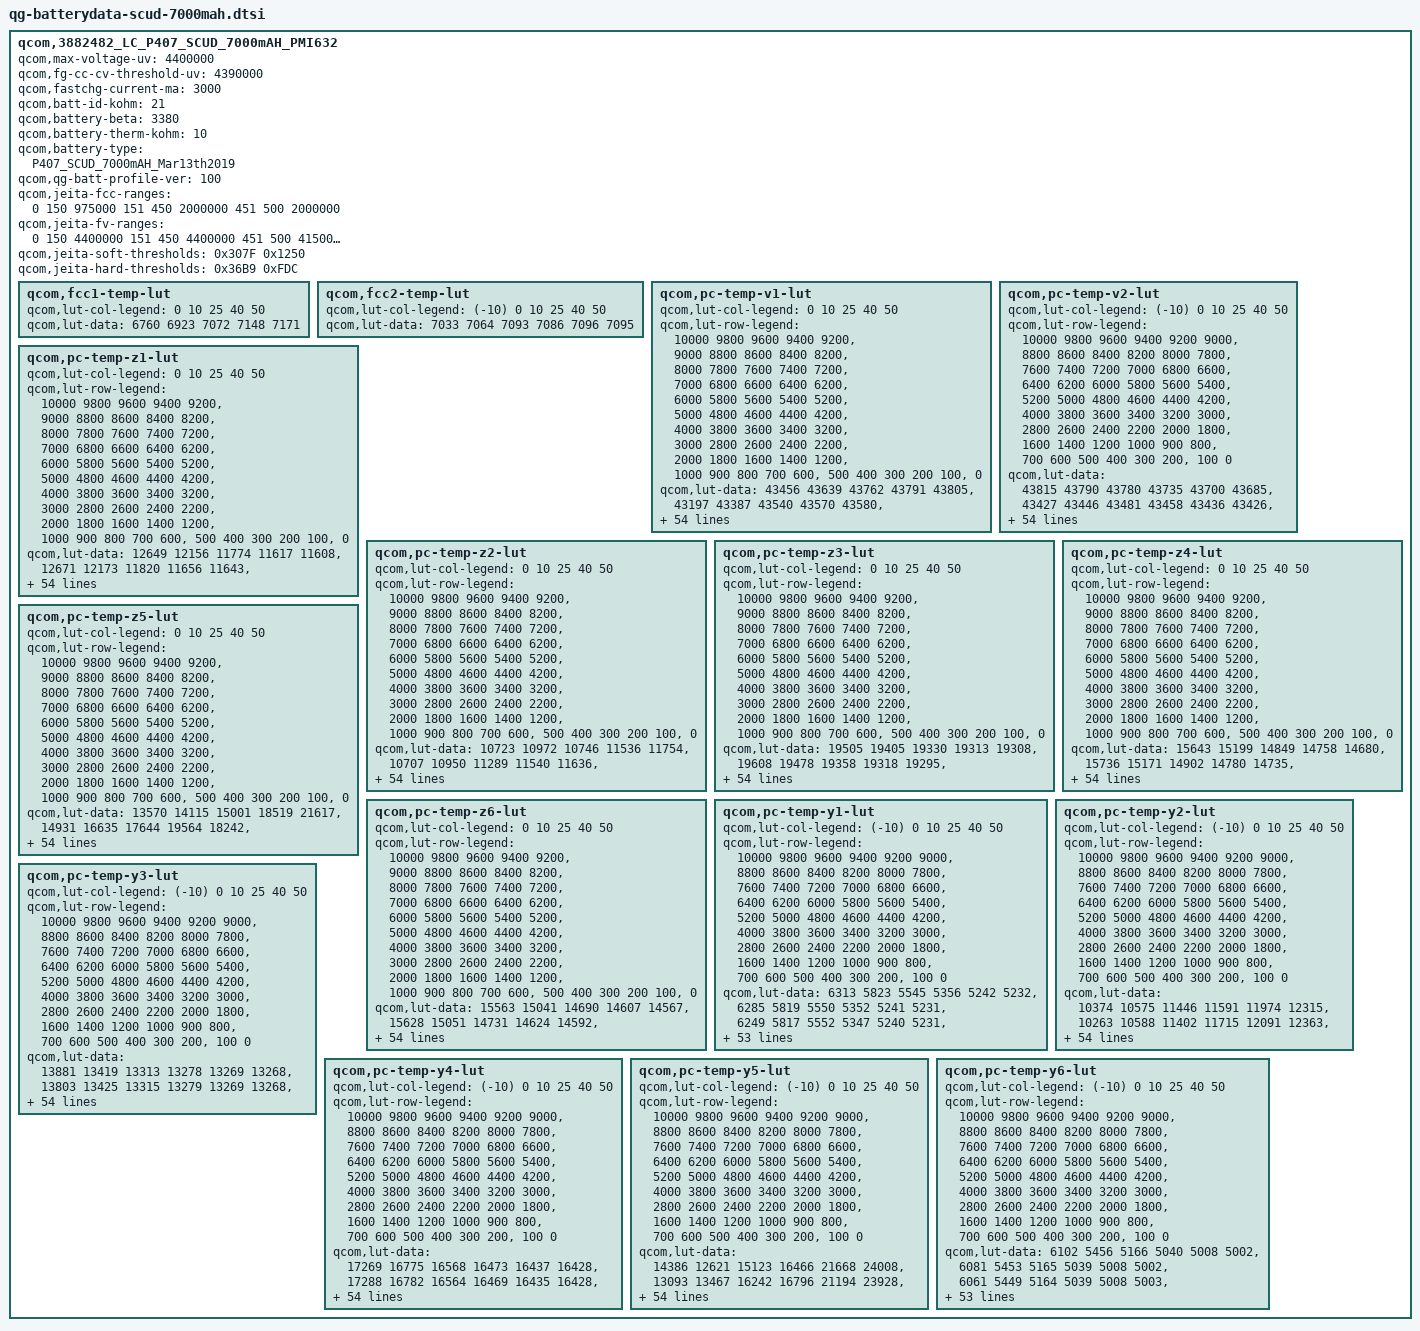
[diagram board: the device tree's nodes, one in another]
qcom,3882482_LC_P407_SCUD_7000mAH_PMI632 {
    /* 3882482_LC_P407_SCUD_7000mAH_PMI632_averaged_MasterSlave_Mar13th2019 */
    qcom,max-voltage-uv = <4400000>;
    qcom,fg-cc-cv-threshold-uv = <4390000>;
    qcom,fastchg-current-ma = <3000>;
    qcom,batt-id-kohm = <21>;
    qcom,battery-beta = <3380>;
    qcom,battery-therm-kohm = <10>;
    qcom,battery-type = "P407_SCUD_7000mAH_Mar13th2019";
    qcom,qg-batt-profile-ver = <100>;

	qcom,jeita-fcc-ranges = <0   150   975000
				151  450  2000000
				451  500  2000000>;
	qcom,jeita-fv-ranges =  <0   150  4400000
				151  450  4400000
				451  500  4150000>;

	/* COOL = 15 DegC, WARM = 45 DegC */
	qcom,jeita-soft-thresholds = <0x307F 0x1250>;
	/* COLD = 0 DegC, HOT = 50 DegC */
	qcom,jeita-hard-thresholds = <0x36B9 0xFDC>;
	qcom,fcc1-temp-lut {
		qcom,lut-col-legend = <0 10 25 40 50>;
		qcom,lut-data = <6760 6923 7072 7148 7171>;
	};

	qcom,fcc2-temp-lut {
		qcom,lut-col-legend = <(-10) 0 10 25 40 50>;
		qcom,lut-data = <7033 7064 7093 7086 7096 7095>;
	};

	qcom,pc-temp-v1-lut {
		qcom,lut-col-legend = <0 10 25 40 50>;
		qcom,lut-row-legend = <10000 9800 9600 9400 9200>,
			<9000 8800 8600 8400 8200>,
			<8000 7800 7600 7400 7200>,
			<7000 6800 6600 6400 6200>,
			<6000 5800 5600 5400 5200>,
			<5000 4800 4600 4400 4200>,
			<4000 3800 3600 3400 3200>,
			<3000 2800 2600 2400 2200>,
			<2000 1800 1600 1400 1200>,
			<1000 900 800 700 600>,
			<500 400 300 200 100>,
			<0>;
		qcom,lut-data = <43456 43639 43762 43791 43805>,
			<43197 43387 43540 43570 43580>,
			<42951 43141 43302 43344 43359>,
			<42713 42901 43063 43115 43132>,
			<42482 42666 42826 42884 42903>,
			<42255 42433 42590 42648 42670>,
			<42033 42203 42356 42413 42436>,
			<41814 41977 42122 42180 42204>,
			<41599 41756 41893 41950 41974>,
			<41398 41539 41666 41723 41746>,
			<41218 41333 41443 41497 41520>,
			<41031 41143 41232 41277 41299>,
			<40807 40947 41033 41062 41082>,
			<40553 40726 40832 40855 40873>,
			<40320 40492 40617 40649 40667>,
			<40115 40282 40405 40446 40466>,
			<39933 40095 40213 40254 40275>,
			<39780 39927 40035 40076 40095>,
			<39650 39780 39869 39905 39923>,
			<39525 39647 39726 39747 39759>,
			<39399 39507 39579 39594 39600>,
			<39277 39360 39376 39401 39415>,
			<39157 39201 39117 39128 39169>,
			<39039 39008 38904 38890 38939>,
			<38925 38794 38745 38760 38794>,
			<38813 38638 38619 38663 38683>,
			<38704 38532 38532 38569 38578>,
			<38604 38452 38466 38476 38476>,
			<38512 38395 38402 38390 38382>,
			<38431 38353 38336 38307 38295>,
			<38369 38312 38274 38232 38215>,
			<38318 38271 38220 38165 38144>,
			<38273 38232 38170 38107 38082>,
			<38234 38194 38123 38052 38023>,
			<38199 38159 38081 38005 37968>,
			<38164 38124 38040 37960 37914>,
			<38132 38093 38000 37912 37855>,
			<38093 38057 37959 37862 37794>,
			<38039 37998 37901 37799 37723>,
			<37966 37903 37810 37713 37639>,
			<37877 37796 37703 37611 37542>,
			<37758 37681 37591 37498 37430>,
			<37621 37549 37464 37367 37301>,
			<37460 37386 37309 37213 37146>,
			<37317 37245 37165 37073 37008>,
			<37233 37161 37079 36984 36925>,
			<37203 37132 37052 36965 36902>,
			<37184 37110 37032 36949 36886>,
			<37158 37094 37019 36931 36869>,
			<37115 37052 36983 36880 36810>,
			<36909 36832 36789 36633 36540>,
			<36466 36402 36378 36206 36107>,
			<35897 35835 35830 35641 35538>,
			<35125 35065 35087 34873 34765>,
			<33916 33864 33953 33695 33574>,
			<30000 30000 30000 30000 30000>;
	};

	qcom,pc-temp-v2-lut {
		qcom,lut-col-legend = <(-10) 0 10 25 40 50>;
		qcom,lut-row-legend = <10000 9800 9600 9400 9200 9000>,
			<8800 8600 8400 8200 8000 7800>,
			<7600 7400 7200 7000 6800 6600>,
			<6400 6200 6000 5800 5600 5400>,
			<5200 5000 4800 4600 4400 4200>,
			<4000 3800 3600 3400 3200 3000>,
			<2800 2600 2400 2200 2000 1800>,
			<1600 1400 1200 1000 900 800>,
			<700 600 500 400 300 200>,
			<100 0>;
		qcom,lut-data = <43815 43790 43780 43735 43700 43685>,
			<43427 43446 43481 43458 43436 43426>,
			<43077 43129 43199 43194 43181 43174>,
			<42764 42843 42936 42943 42935 42932>,
			<42483 42586 42692 42707 42700 42698>,
			<42235 42338 42452 42473 42466 42465>,
			<42027 42091 42213 42239 42232 42232>,
			<41833 41851 41977 42007 42000 42000>,
			<41599 41613 41748 41778 41771 41772>,
			<41319 41375 41523 41551 41545 41546>,
			<41099 41162 41305 41329 41322 41323>,
			<40985 40997 41101 41113 41105 41105>,
			<40883 40836 40900 40901 40891 40891>,
			<40638 40616 40692 40696 40686 40686>,
			<40130 40332 40477 40495 40485 40487>,
			<39720 40059 40263 40295 40291 40294>,
			<39516 39816 40052 40092 40099 40107>,
			<39356 39591 39842 39900 39916 39927>,
			<39190 39397 39630 39734 39748 39759>,
			<39027 39223 39417 39585 39592 39599>,
			<38863 39053 39217 39406 39409 39415>,
			<38686 38880 39026 39161 39173 39183>,
			<38521 38716 38853 38922 38945 38959>,
			<38401 38568 38703 38754 38774 38786>,
			<38307 38429 38569 38619 38631 38640>,
			<38227 38307 38450 38500 38509 38515>,
			<38159 38196 38343 38395 38402 38407>,
			<38099 38104 38245 38298 38307 38310>,
			<38042 38038 38156 38208 38218 38220>,
			<37989 37985 38073 38124 38138 38137>,
			<37938 37937 37995 38049 38064 38063>,
			<37888 37893 37921 37981 37996 37993>,
			<37839 37852 37860 37918 37932 37927>,
			<37788 37811 37816 37857 37871 37865>,
			<37739 37771 37781 37801 37810 37804>,
			<37686 37726 37743 37744 37736 37720>,
			<37627 37675 37703 37686 37643 37606>,
			<37564 37618 37659 37625 37550 37495>,
			<37494 37555 37604 37557 37469 37408>,
			<37420 37483 37538 37485 37392 37329>,
			<37343 37401 37457 37405 37311 37246>,
			<37263 37304 37352 37312 37222 37159>,
			<37183 37189 37231 37202 37114 37050>,
			<37105 37065 37096 37068 36980 36916>,
			<37025 36950 36964 36932 36857 36799>,
			<36932 36846 36876 36883 36823 36768>,
			<36880 36799 36839 36866 36812 36753>,
			<36829 36744 36808 36848 36792 36735>,
			<36764 36685 36761 36816 36754 36697>,
			<36670 36590 36668 36750 36673 36607>,
			<36503 36405 36458 36532 36392 36311>,
			<36206 36056 36038 36090 35919 35838>,
			<35717 35505 35429 35497 35292 35209>,
			<34992 34699 34606 34699 34427 34348>,
			<33903 33435 33349 33490 33089 33051>,
			<31795 29561 29447 30820 29743 29527>;
	};

	qcom,pc-temp-z1-lut {
		qcom,lut-col-legend = <0 10 25 40 50>;
		qcom,lut-row-legend = <10000 9800 9600 9400 9200>,
			<9000 8800 8600 8400 8200>,
			<8000 7800 7600 7400 7200>,
			<7000 6800 6600 6400 6200>,
			<6000 5800 5600 5400 5200>,
			<5000 4800 4600 4400 4200>,
			<4000 3800 3600 3400 3200>,
			<3000 2800 2600 2400 2200>,
			<2000 1800 1600 1400 1200>,
			<1000 900 800 700 600>,
			<500 400 300 200 100>,
			<0>;
		qcom,lut-data = <12649 12156 11774 11617 11608>,
			<12671 12173 11820 11656 11643>,
			<12690 12182 11818 11662 11654>,
			<12705 12189 11810 11669 11661>,
			<12709 12197 11808 11673 11665>,
			<12710 12199 11806 11673 11668>,
			<12710 12191 11805 11674 11671>,
			<12700 12182 11803 11676 11674>,
			<12682 12179 11801 11680 11678>,
			<12677 12177 11802 11683 11682>,
			<12687 12179 11803 11687 11687>,
			<12695 12188 11805 11689 11690>,
			<12696 12194 11808 11691 11692>,
			<12693 12188 11810 11692 11692>,
			<12689 12175 11809 11692 11693>,
			<12670 12167 11807 11692 11694>,
			<12648 12164 11806 11692 11694>,
			<12646 12165 11806 11692 11694>,
			<12655 12171 11806 11692 11694>,
			<12663 12179 11809 11693 11694>,
			<12669 12182 11812 11694 11696>,
			<12673 12183 11814 11694 11697>,
			<12669 12184 11815 11695 11697>,
			<12658 12188 11816 11697 11698>,
			<12651 12193 11818 11699 11699>,
			<12659 12195 11821 11701 11701>,
			<12673 12192 11824 11704 11702>,
			<12678 12189 11827 11707 11702>,
			<12676 12192 11830 11709 11703>,
			<12673 12202 11834 11711 11705>,
			<12670 12209 11838 11712 11708>,
			<12664 12207 11841 11714 11710>,
			<12662 12204 11844 11716 11712>,
			<12674 12206 11847 11718 11713>,
			<12692 12209 11850 11720 11715>,
			<12699 12214 11853 11721 11716>,
			<12700 12223 11856 11723 11717>,
			<12702 12234 11859 11725 11718>,
			<12704 12239 11862 11727 11719>,
			<12708 12246 11865 11729 11720>,
			<12711 12248 11868 11730 11721>,
			<12716 12244 11874 11731 11722>,
			<12719 12242 11879 11731 11722>,
			<12715 12243 11881 11734 11724>,
			<12693 12251 11885 11738 11726>,
			<12676 12242 11887 11740 11727>,
			<12684 12241 11889 11740 11727>,
			<12694 12241 11889 11740 11728>,
			<12688 12246 11886 11742 11728>,
			<12691 12249 11897 11743 11729>,
			<12685 12252 11897 11746 11730>,
			<12690 12273 11902 11750 11736>,
			<12746 12281 11920 11758 11741>,
			<12713 12315 11934 11768 11751>,
			<12713 12315 11934 11768 11751>,
			<12713 12315 11934 11768 11751>;
	};

	qcom,pc-temp-z2-lut {
		qcom,lut-col-legend = <0 10 25 40 50>;
		qcom,lut-row-legend = <10000 9800 9600 9400 9200>,
			<9000 8800 8600 8400 8200>,
			<8000 7800 7600 7400 7200>,
			<7000 6800 6600 6400 6200>,
			<6000 5800 5600 5400 5200>,
			<5000 4800 4600 4400 4200>,
			<4000 3800 3600 3400 3200>,
			<3000 2800 2600 2400 2200>,
			<2000 1800 1600 1400 1200>,
			<1000 900 800 700 600>,
			<500 400 300 200 100>,
			<0>;
		qcom,lut-data = <10723 10972 10746 11536 11754>,
			<10707 10950 11289 11540 11636>,
			<10729 10934 11301 11622 11674>,
			<10763 10922 11303 11725 11673>,
			<10802 10910 11309 11761 11711>,
			<10849 10895 11321 11756 11891>,
			<10884 10869 11319 11752 12013>,
			<10912 10849 11298 11720 11983>,
			<10937 10847 11278 11661 11920>,
			<10944 10847 11264 11633 11860>,
			<10937 10847 11255 11621 11731>,
			<10924 10844 11256 11617 11606>,
			<10884 10840 11264 11648 11555>,
			<10813 10836 11275 11697 11547>,
			<10781 10833 11297 11650 11572>,
			<10779 10841 11329 11492 11601>,
			<10779 10913 11356 11429 11625>,
			<10778 10994 11386 11470 11648>,
			<10778 11036 11406 11514 11666>,
			<10777 11066 11414 11527 11691>,
			<10763 11075 11422 11536 11752>,
			<10743 11071 11430 11572 11793>,
			<10731 11066 11439 11725 11811>,
			<10720 11070 11438 11824 11796>,
			<10713 11080 11421 11709 11801>,
			<10718 11089 11405 11518 11848>,
			<10733 11101 11406 11516 11880>,
			<10746 11109 11413 11721 11910>,
			<10755 11108 11421 11855 11909>,
			<10764 11104 11448 11828 11769>,
			<10777 11102 11473 11777 11586>,
			<10794 11107 11462 11737 11555>,
			<10811 11116 11426 11697 11531>,
			<10825 11124 11414 11679 11516>,
			<10839 11132 11435 11701 11568>,
			<10857 11141 11460 11739 11655>,
			<10882 11151 11468 11774 11709>,
			<10907 11162 11474 11812 11754>,
			<10927 11175 11489 11850 11801>,
			<10947 11193 11538 11900 11897>,
			<10967 11204 11575 11934 11980>,
			<10991 11205 11572 11894 11963>,
			<11027 11207 11565 11817 11909>,
			<11089 11225 11571 11814 11878>,
			<11463 11390 11632 11840 11914>,
			<11787 11570 11666 11916 11943>,
			<11743 11578 11677 11890 11877>,
			<11470 11571 11658 11842 11903>,
			<11412 11889 11824 11848 11968>,
			<11191 11823 11783 12026 12287>,
			<11031 11718 11930 12215 11813>,
			<11401 11719 11973 11961 11600>,
			<11000 11694 11904 11823 11405>,
			<10723 11540 11946 11588 11426>,
			<10723 11540 11946 11588 11426>,
			<10723 11540 11946 11588 11426>;
	};

	qcom,pc-temp-z3-lut {
		qcom,lut-col-legend = <0 10 25 40 50>;
		qcom,lut-row-legend = <10000 9800 9600 9400 9200>,
			<9000 8800 8600 8400 8200>,
			<8000 7800 7600 7400 7200>,
			<7000 6800 6600 6400 6200>,
			<6000 5800 5600 5400 5200>,
			<5000 4800 4600 4400 4200>,
			<4000 3800 3600 3400 3200>,
			<3000 2800 2600 2400 2200>,
			<2000 1800 1600 1400 1200>,
			<1000 900 800 700 600>,
			<500 400 300 200 100>,
			<0>;
		qcom,lut-data = <19505 19405 19330 19313 19308>,
			<19608 19478 19358 19318 19295>,
			<19640 19515 19383 19330 19306>,
			<19655 19523 19394 19334 19315>,
			<19650 19526 19395 19337 19321>,
			<19622 19526 19395 19340 19325>,
			<19595 19521 19395 19343 19327>,
			<19580 19515 19393 19342 19327>,
			<19569 19507 19392 19340 19326>,
			<19562 19499 19391 19338 19325>,
			<19554 19494 19391 19336 19323>,
			<19549 19490 19388 19334 19320>,
			<19557 19488 19377 19333 19315>,
			<19581 19489 19369 19332 19310>,
			<19594 19491 19369 19328 19308>,
			<19588 19488 19370 19321 19308>,
			<19579 19464 19366 19317 19308>,
			<19570 19441 19354 19316 19305>,
			<19557 19438 19348 19315 19302>,
			<19550 19437 19350 19315 19301>,
			<19554 19438 19356 19314 19301>,
			<19563 19449 19365 19315 19302>,
			<19572 19464 19381 19324 19305>,
			<19583 19475 19387 19330 19308>,
			<19593 19485 19384 19324 19303>,
			<19600 19487 19381 19314 19294>,
			<19605 19486 19377 19312 19294>,
			<19607 19485 19372 19315 19305>,
			<19608 19482 19371 19319 19314>,
			<19607 19476 19373 19327 19318>,
			<19603 19470 19376 19337 19321>,
			<19592 19466 19377 19338 19320>,
			<19582 19463 19378 19337 19317>,
			<19574 19460 19378 19334 19313>,
			<19567 19459 19376 19330 19311>,
			<19560 19456 19374 19326 19309>,
			<19553 19451 19372 19324 19308>,
			<19547 19447 19370 19323 19307>,
			<19542 19447 19369 19321 19307>,
			<19537 19449 19368 19319 19306>,
			<19532 19450 19368 19317 19304>,
			<19522 19446 19366 19316 19303>,
			<19512 19440 19363 19316 19302>,
			<19505 19436 19359 19313 19301>,
			<19461 19419 19354 19310 19300>,
			<19404 19388 19339 19311 19295>,
			<19385 19388 19341 19304 19295>,
			<19314 19386 19341 19303 19295>,
			<19307 19350 19321 19303 19290>,
			<19293 19361 19324 19299 19284>,
			<19290 19377 19321 19292 19302>,
			<19315 19365 19316 19297 19304>,
			<19321 19355 19310 19303 19308>,
			<19325 19338 19305 19307 19299>,
			<19325 19338 19305 19307 19299>,
			<19325 19338 19305 19307 19299>;
	};

	qcom,pc-temp-z4-lut {
		qcom,lut-col-legend = <0 10 25 40 50>;
		qcom,lut-row-legend = <10000 9800 9600 9400 9200>,
			<9000 8800 8600 8400 8200>,
			<8000 7800 7600 7400 7200>,
			<7000 6800 6600 6400 6200>,
			<6000 5800 5600 5400 5200>,
			<5000 4800 4600 4400 4200>,
			<4000 3800 3600 3400 3200>,
			<3000 2800 2600 2400 2200>,
			<2000 1800 1600 1400 1200>,
			<1000 900 800 700 600>,
			<500 400 300 200 100>,
			<0>;
		qcom,lut-data = <15643 15199 14849 14758 14680>,
			<15736 15171 14902 14780 14735>,
			<15647 15130 14881 14784 14746>,
			<15506 15063 14855 14772 14742>,
			<15413 14984 14827 14760 14735>,
			<15347 14928 14797 14745 14722>,
			<15290 14885 14773 14730 14710>,
			<15238 14852 14754 14718 14700>,
			<15191 14826 14737 14707 14691>,
			<15149 14806 14720 14697 14683>,
			<15113 14788 14705 14688 14675>,
			<15078 14771 14697 14679 14669>,
			<15040 14756 14692 14668 14665>,
			<15000 14741 14687 14660 14662>,
			<14965 14729 14682 14658 14656>,
			<14939 14726 14677 14657 14649>,
			<14916 14727 14674 14656 14643>,
			<14897 14727 14673 14649 14639>,
			<14881 14722 14671 14640 14635>,
			<14864 14709 14661 14638 14632>,
			<14843 14697 14650 14636 14631>,
			<14819 14686 14659 14642 14633>,
			<14797 14679 14697 14691 14674>,
			<14775 14694 14725 14733 14717>,
			<14757 14732 14740 14737 14724>,
			<14744 14748 14749 14737 14726>,
			<14735 14748 14746 14733 14723>,
			<14733 14747 14732 14720 14702>,
			<14733 14742 14719 14703 14680>,
			<14734 14730 14704 14683 14666>,
			<14734 14719 14691 14663 14653>,
			<14735 14711 14678 14652 14645>,
			<14735 14703 14668 14644 14638>,
			<14734 14696 14661 14642 14636>,
			<14732 14689 14656 14642 14636>,
			<14730 14684 14654 14642 14637>,
			<14727 14681 14653 14643 14639>,
			<14723 14679 14653 14646 14645>,
			<14719 14679 14654 14650 14650>,
			<14714 14680 14661 14657 14653>,
			<14713 14681 14667 14663 14655>,
			<14717 14680 14664 14661 14654>,
			<14718 14679 14661 14658 14651>,
			<14710 14678 14662 14661 14653>,
			<14695 14668 14658 14660 14653>,
			<14724 14671 14653 14644 14644>,
			<14743 14666 14644 14641 14638>,
			<14820 14663 14635 14631 14624>,
			<14826 14699 14650 14621 14618>,
			<14834 14683 14646 14626 14627>,
			<14836 14672 14663 14652 14623>,
			<14826 14695 14675 14650 14625>,
			<14833 14711 14685 14645 14622>,
			<14842 14739 14693 14643 14632>,
			<14842 14739 14693 14643 14632>,
			<14842 14739 14693 14643 14632>;
	};

	qcom,pc-temp-z5-lut {
		qcom,lut-col-legend = <0 10 25 40 50>;
		qcom,lut-row-legend = <10000 9800 9600 9400 9200>,
			<9000 8800 8600 8400 8200>,
			<8000 7800 7600 7400 7200>,
			<7000 6800 6600 6400 6200>,
			<6000 5800 5600 5400 5200>,
			<5000 4800 4600 4400 4200>,
			<4000 3800 3600 3400 3200>,
			<3000 2800 2600 2400 2200>,
			<2000 1800 1600 1400 1200>,
			<1000 900 800 700 600>,
			<500 400 300 200 100>,
			<0>;
		qcom,lut-data = <13570 14115 15001 18519 21617>,
			<14931 16635 17644 19564 18242>,
			<15567 18230 19729 21287 20089>,
			<15913 19036 20846 21928 21813>,
			<15904 19580 21180 22287 23122>,
			<15690 19958 21394 22977 24349>,
			<15536 20241 21698 23522 25075>,
			<15542 20393 22082 23481 25235>,
			<15567 20443 22577 23298 25179>,
			<15594 20476 23664 23365 25234>,
			<15577 20584 24863 23656 25377>,
			<15574 21091 24823 24165 25401>,
			<15968 21917 23599 25666 24667>,
			<16965 23818 22848 27165 23818>,
			<17501 26147 23583 26570 24157>,
			<17519 26298 24626 24483 25972>,
			<17507 23376 24394 23711 27216>,
			<17504 20936 22807 25192 27417>,
			<17406 21202 21994 27471 27605>,
			<17395 22500 24180 29235 29059>,
			<17990 24698 29088 31165 32869>,
			<19273 31848 42102 34902 35397>,
			<20927 41876 65535 44702 36597>,
			<23590 53780 65535 51454 36880>,
			<26980 65535 65535 43003 31626>,
			<31428 65535 49619 27873 21988>,
			<36726 65535 40417 23370 19723>,
			<40545 59126 33272 22256 21262>,
			<43529 52931 31168 21865 22916>,
			<45325 46469 31415 24714 25243>,
			<44528 42382 31934 30208 29016>,
			<41070 39945 33617 35178 31416>,
			<37833 38544 37220 40355 33459>,
			<35602 38639 40553 43221 35596>,
			<33706 39490 44045 44320 39066>,
			<32384 39931 46355 44921 42282>,
			<31333 38690 46658 44505 42123>,
			<30601 37109 46790 42836 39819>,
			<30727 37943 46630 40696 37044>,
			<31652 41856 44709 35681 33243>,
			<31837 43896 42144 30867 29551>,
			<29751 40086 39917 29758 27665>,
			<29028 36773 37401 29129 26356>,
			<30975 36468 33825 26136 24852>,
			<30437 35515 33276 25003 24141>,
			<20816 26690 27847 27804 22736>,
			<19173 26960 29385 24767 23460>,
			<13915 26514 30546 26021 26990>,
			<13624 17999 21307 28878 26437>,
			<13194 20063 22119 25267 20995>,
			<13322 24197 20022 17860 24975>,
			<13922 19613 18228 17970 24517>,
			<13772 17620 16518 18882 25675>,
			<13532 15402 15282 19724 22636>,
			<13532 15402 15282 19724 22636>,
			<13532 15402 15282 19724 22636>;
	};

	qcom,pc-temp-z6-lut {
		qcom,lut-col-legend = <0 10 25 40 50>;
		qcom,lut-row-legend = <10000 9800 9600 9400 9200>,
			<9000 8800 8600 8400 8200>,
			<8000 7800 7600 7400 7200>,
			<7000 6800 6600 6400 6200>,
			<6000 5800 5600 5400 5200>,
			<5000 4800 4600 4400 4200>,
			<4000 3800 3600 3400 3200>,
			<3000 2800 2600 2400 2200>,
			<2000 1800 1600 1400 1200>,
			<1000 900 800 700 600>,
			<500 400 300 200 100>,
			<0>;
		qcom,lut-data = <15563 15041 14690 14607 14567>,
			<15628 15051 14731 14624 14592>,
			<15588 15051 14731 14631 14604>,
			<15518 15026 14729 14632 14608>,
			<15458 14983 14720 14631 14608>,
			<15402 14950 14704 14626 14606>,
			<15354 14924 14692 14621 14603>,
			<15316 14901 14683 14616 14600>,
			<15284 14882 14674 14610 14596>,
			<15256 14866 14667 14605 14592>,
			<15231 14853 14660 14601 14589>,
			<15209 14843 14653 14597 14585>,
			<15192 14834 14646 14592 14581>,
			<15177 14826 14641 14588 14577>,
			<15163 14817 14638 14584 14573>,
			<15147 14808 14636 14581 14570>,
			<15131 14796 14632 14577 14567>,
			<15116 14786 14625 14573 14563>,
			<15103 14780 14621 14570 14560>,
			<15093 14775 14619 14568 14559>,
			<15085 14774 14618 14567 14558>,
			<15079 14777 14625 14570 14560>,
			<15075 14782 14650 14596 14580>,
			<15072 14795 14666 14617 14599>,
			<15070 14818 14672 14616 14599>,
			<15069 14827 14674 14612 14597>,
			<15068 14827 14672 14608 14595>,
			<15068 14826 14665 14605 14592>,
			<15070 14823 14659 14601 14589>,
			<15072 14817 14655 14597 14585>,
			<15071 14811 14651 14594 14581>,
			<15066 14806 14647 14590 14577>,
			<15062 14802 14643 14587 14573>,
			<15060 14799 14640 14584 14570>,
			<15058 14797 14638 14581 14568>,
			<15056 14795 14636 14579 14568>,
			<15054 14793 14636 14579 14568>,
			<15052 14792 14636 14580 14570>,
			<15050 14793 14636 14581 14572>,
			<15048 14797 14639 14583 14573>,
			<15047 14800 14642 14585 14573>,
			<15045 14800 14641 14584 14572>,
			<15043 14799 14639 14582 14570>,
			<15039 14799 14639 14583 14571>,
			<15012 14790 14636 14581 14571>,
			<15000 14777 14627 14575 14565>,
			<14999 14776 14625 14571 14561>,
			<14994 14773 14622 14566 14556>,
			<14995 14773 14617 14561 14550>,
			<14995 14773 14618 14562 14551>,
			<14998 14780 14625 14570 14560>,
			<15014 14788 14630 14573 14563>,
			<15030 14797 14634 14575 14565>,
			<15052 14812 14640 14579 14567>,
			<15052 14812 14640 14579 14567>,
			<15052 14812 14640 14579 14567>;
	};

	qcom,pc-temp-y1-lut {
		qcom,lut-col-legend = <(-10) 0 10 25 40 50>;
		qcom,lut-row-legend = <10000 9800 9600 9400 9200 9000>,
			<8800 8600 8400 8200 8000 7800>,
			<7600 7400 7200 7000 6800 6600>,
			<6400 6200 6000 5800 5600 5400>,
			<5200 5000 4800 4600 4400 4200>,
			<4000 3800 3600 3400 3200 3000>,
			<2800 2600 2400 2200 2000 1800>,
			<1600 1400 1200 1000 900 800>,
			<700 600 500 400 300 200>,
			<100 0>;
		qcom,lut-data = <6313 5823 5545 5356 5242 5232>,
			<6285 5819 5550 5352 5241 5231>,
			<6249 5817 5552 5347 5240 5231>,
			<6212 5817 5553 5342 5238 5230>,
			<6183 5818 5553 5337 5237 5230>,
			<6168 5820 5552 5333 5236 5229>,
			<6164 5825 5551 5330 5236 5228>,
			<6164 5829 5549 5326 5235 5227>,
			<6164 5825 5547 5322 5235 5227>,
			<6160 5804 5544 5319 5234 5227>,
			<6158 5793 5543 5316 5234 5227>,
			<6164 5802 5542 5316 5232 5227>,
			<6174 5814 5540 5315 5230 5227>,
			<6176 5816 5537 5314 5229 5227>,
			<6176 5813 5532 5314 5229 5226>,
			<6175 5813 5531 5313 5229 5226>,
			<6168 5810 5533 5312 5230 5226>,
			<6157 5807 5536 5311 5231 5227>,
			<6157 5803 5535 5312 5231 5227>,
			<6169 5797 5534 5313 5231 5228>,
			<6177 5794 5534 5314 5231 5228>,
			<6179 5801 5540 5315 5231 5228>,
			<6175 5808 5546 5317 5231 5227>,
			<6172 5808 5548 5318 5232 5226>,
			<6175 5802 5549 5320 5234 5224>,
			<6179 5799 5548 5321 5235 5224>,
			<6176 5799 5545 5324 5236 5227>,
			<6168 5799 5543 5327 5237 5230>,
			<6163 5802 5543 5329 5239 5231>,
			<6158 5811 5543 5332 5241 5233>,
			<6154 5818 5544 5334 5242 5234>,
			<6156 5825 5546 5335 5243 5235>,
			<6159 5829 5548 5336 5244 5236>,
			<6152 5825 5552 5338 5246 5238>,
			<6133 5812 5558 5341 5248 5239>,
			<6127 5803 5556 5344 5250 5240>,
			<6139 5802 5548 5347 5251 5241>,
			<6151 5805 5547 5350 5252 5241>,
			<6146 5808 5554 5352 5254 5241>,
			<6130 5807 5561 5355 5255 5242>,
			<6120 5802 5563 5356 5254 5243>,
			<6120 5805 5565 5357 5254 5245>,
			<6124 5812 5570 5359 5255 5245>,
			<6130 5797 5575 5362 5257 5245>,
			<6148 5795 5569 5361 5259 5246>,
			<6149 5809 5578 5366 5261 5248>,
			<6126 5795 5583 5371 5262 5248>,
			<6170 5801 5576 5371 5262 5247>,
			<6173 5813 5586 5372 5262 5248>,
			<6143 5811 5576 5372 5263 5250>,
			<6172 5814 5579 5380 5265 5250>,
			<6154 5815 5589 5385 5269 5254>,
			<6194 5836 5589 5394 5276 5258>,
			<6247 5867 5610 5410 5280 5263>,
			<6247 5867 5610 5410 5280 5263>,
			<6247 5867 5610 5410 5280 5263>;
	};

	qcom,pc-temp-y2-lut {
		qcom,lut-col-legend = <(-10) 0 10 25 40 50>;
		qcom,lut-row-legend = <10000 9800 9600 9400 9200 9000>,
			<8800 8600 8400 8200 8000 7800>,
			<7600 7400 7200 7000 6800 6600>,
			<6400 6200 6000 5800 5600 5400>,
			<5200 5000 4800 4600 4400 4200>,
			<4000 3800 3600 3400 3200 3000>,
			<2800 2600 2400 2200 2000 1800>,
			<1600 1400 1200 1000 900 800>,
			<700 600 500 400 300 200>,
			<100 0>;
		qcom,lut-data = <10374 10575 11446 11591 11974 12315>,
			<10263 10588 11402 11715 12091 12363>,
			<10218 10613 11357 11812 12164 12381>,
			<10223 10643 11313 11882 12200 12377>,
			<10262 10671 11276 11924 12207 12359>,
			<10319 10691 11250 11936 12194 12335>,
			<10433 10709 11230 11878 12138 12290>,
			<10566 10725 11217 11799 12064 12237>,
			<10614 10731 11220 11793 12019 12194>,
			<10634 10757 11237 11816 11981 12143>,
			<10656 10798 11248 11831 11971 12120>,
			<10710 10947 11252 11821 11976 12101>,
			<10781 11115 11257 11808 11987 12080>,
			<10782 11146 11301 11814 12010 12080>,
			<10571 11152 11427 11832 12046 12094>,
			<10401 11162 11504 11854 12089 12111>,
			<10086 11198 11528 11880 12185 12136>,
			<9726 11254 11543 11915 12298 12165>,
			<9688 11310 11558 11981 12375 12246>,
			<9686 11373 11571 12076 12441 12440>,
			<9684 11443 11596 12110 12456 12521>,
			<9681 11542 11667 12095 12388 12436>,
			<9679 11620 11745 12082 12326 12339>,
			<9677 11625 11796 12110 12381 12342>,
			<9676 11608 11838 12174 12485 12390>,
			<9674 11526 11874 12216 12513 12442>,
			<9673 10753 11907 12252 12514 12605>,
			<9671 9976 11939 12285 12527 12710>,
			<9670 10128 11972 12299 12548 12700>,
			<9669 10549 12004 12310 12575 12713>,
			<9668 10576 12032 12318 12606 12712>,
			<9667 10101 12062 12345 12638 12694>,
			<9666 9751 12077 12369 12647 12689>,
			<9665 9724 12036 12355 12671 12809>,
			<9664 9708 11959 12330 12723 12976>,
			<9664 9699 11909 12335 12730 13001>,
			<9663 9693 11875 12369 12675 12950>,
			<9663 9687 11837 12388 12658 12896>,
			<9663 9681 11793 12398 12698 12774>,
			<9662 9676 11739 12410 12717 12652>,
			<9662 9672 11659 12406 12662 12661>,
			<9662 9668 11544 12345 12569 12694>,
			<9662 9666 11446 12242 12532 12685>,
			<9661 9663 11351 12207 12503 12672>,
			<9661 9662 11185 12108 12581 12590>,
			<9661 9661 11011 12079 12509 12520>,
			<9660 9661 10569 12048 12412 12467>,
			<9660 9660 10369 12096 12392 12359>,
			<9660 9659 10294 11987 12316 12097>,
			<9660 9659 9929 11997 12379 12173>,
			<9659 9658 9763 11888 12259 12183>,
			<9658 9658 9702 11799 12144 12068>,
			<9655 9657 9675 11645 11945 11884>,
			<9653 9654 9664 11437 11864 11783>,
			<9653 9654 9664 11437 11864 11783>,
			<9653 9654 9664 11437 11864 11783>;
	};

	qcom,pc-temp-y3-lut {
		qcom,lut-col-legend = <(-10) 0 10 25 40 50>;
		qcom,lut-row-legend = <10000 9800 9600 9400 9200 9000>,
			<8800 8600 8400 8200 8000 7800>,
			<7600 7400 7200 7000 6800 6600>,
			<6400 6200 6000 5800 5600 5400>,
			<5200 5000 4800 4600 4400 4200>,
			<4000 3800 3600 3400 3200 3000>,
			<2800 2600 2400 2200 2000 1800>,
			<1600 1400 1200 1000 900 800>,
			<700 600 500 400 300 200>,
			<100 0>;
		qcom,lut-data = <13881 13419 13313 13278 13269 13268>,
			<13803 13425 13315 13279 13269 13268>,
			<13746 13428 13319 13279 13270 13268>,
			<13708 13430 13322 13280 13270 13268>,
			<13687 13431 13324 13280 13271 13268>,
			<13681 13431 13325 13281 13271 13268>,
			<13701 13428 13325 13281 13271 13268>,
			<13731 13423 13325 13281 13271 13269>,
			<13701 13424 13326 13281 13271 13269>,
			<13540 13431 13328 13281 13271 13269>,
			<13444 13435 13329 13281 13271 13269>,
			<13467 13414 13330 13283 13273 13269>,
			<13500 13386 13332 13286 13275 13269>,
			<13500 13385 13332 13287 13275 13270>,
			<13472 13393 13332 13289 13275 13272>,
			<13445 13398 13331 13290 13274 13273>,
			<13421 13390 13330 13290 13275 13272>,
			<13403 13377 13329 13290 13277 13272>,
			<13403 13370 13326 13291 13277 13273>,
			<13410 13365 13321 13292 13278 13275>,
			<13414 13359 13317 13292 13278 13275>,
			<13406 13349 13313 13288 13276 13273>,
			<13396 13340 13310 13283 13273 13270>,
			<13395 13335 13306 13281 13271 13268>,
			<13400 13333 13303 13279 13270 13267>,
			<13408 13326 13302 13279 13269 13267>,
			<13421 13296 13301 13279 13270 13267>,
			<13440 13269 13301 13280 13270 13267>,
			<13458 13274 13301 13279 13270 13267>,
			<13478 13288 13300 13279 13271 13268>,
			<13498 13291 13299 13280 13271 13268>,
			<13522 13286 13295 13281 13271 13268>,
			<13549 13285 13292 13282 13271 13268>,
			<13577 13295 13294 13282 13272 13269>,
			<13606 13310 13298 13282 13272 13269>,
			<13637 13322 13301 13282 13273 13269>,
			<13669 13333 13302 13282 13272 13268>,
			<13704 13348 13303 13281 13271 13267>,
			<13743 13372 13304 13281 13270 13267>,
			<13786 13405 13305 13280 13269 13267>,
			<13830 13442 13306 13279 13269 13267>,
			<13871 13487 13306 13277 13269 13267>,
			<13916 13544 13306 13278 13269 13267>,
			<13970 13623 13308 13281 13269 13267>,
			<14038 13709 13310 13281 13269 13267>,
			<14037 13758 13312 13281 13270 13269>,
			<14097 13830 13315 13281 13272 13269>,
			<14165 13904 13326 13284 13273 13272>,
			<14240 13986 13337 13285 13274 13273>,
			<14334 14062 13357 13290 13280 13276>,
			<14462 14138 13382 13289 13277 13271>,
			<14705 14225 13411 13290 13275 13272>,
			<15277 14411 13491 13296 13277 13272>,
			<16379 14916 13713 13305 13281 13275>,
			<16379 14916 13713 13305 13281 13275>,
			<16379 14916 13713 13305 13281 13275>;
	};

	qcom,pc-temp-y4-lut {
		qcom,lut-col-legend = <(-10) 0 10 25 40 50>;
		qcom,lut-row-legend = <10000 9800 9600 9400 9200 9000>,
			<8800 8600 8400 8200 8000 7800>,
			<7600 7400 7200 7000 6800 6600>,
			<6400 6200 6000 5800 5600 5400>,
			<5200 5000 4800 4600 4400 4200>,
			<4000 3800 3600 3400 3200 3000>,
			<2800 2600 2400 2200 2000 1800>,
			<1600 1400 1200 1000 900 800>,
			<700 600 500 400 300 200>,
			<100 0>;
		qcom,lut-data = <17269 16775 16568 16473 16437 16428>,
			<17288 16782 16564 16469 16435 16428>,
			<17298 16792 16563 16467 16434 16428>,
			<17302 16802 16562 16466 16434 16428>,
			<17300 16811 16563 16466 16435 16429>,
			<17294 16817 16563 16466 16435 16429>,
			<17203 16822 16564 16468 16437 16430>,
			<17075 16827 16566 16471 16441 16431>,
			<17110 16823 16568 16475 16444 16433>,
			<17374 16805 16572 16480 16449 16436>,
			<17530 16797 16579 16485 16452 16440>,
			<17512 16906 16587 16488 16453 16444>,
			<17469 17046 16598 16490 16455 16448>,
			<17358 17039 16624 16496 16458 16450>,
			<17091 16933 16667 16506 16466 16452>,
			<16947 16842 16685 16516 16473 16455>,
			<16964 16788 16681 16528 16478 16461>,
			<16987 16747 16672 16541 16485 16468>,
			<16968 16726 16648 16558 16497 16478>,
			<16902 16712 16601 16579 16516 16491>,
			<16837 16696 16564 16582 16521 16493>,
			<16779 16677 16538 16529 16492 16475>,
			<16734 16655 16520 16472 16459 16453>,
			<16721 16626 16514 16460 16446 16442>,
			<16715 16587 16511 16455 16438 16434>,
			<16712 16574 16508 16454 16436 16432>,
			<16710 16604 16507 16454 16438 16433>,
			<16708 16636 16506 16456 16440 16435>,
			<16707 16626 16505 16459 16444 16439>,
			<16708 16602 16502 16463 16448 16444>,
			<16709 16599 16501 16467 16454 16449>,
			<16711 16620 16501 16470 16462 16455>,
			<16713 16634 16501 16474 16468 16461>,
			<16714 16634 16502 16476 16473 16466>,
			<16715 16635 16504 16478 16476 16470>,
			<16717 16638 16507 16478 16473 16467>,
			<16719 16645 16515 16473 16457 16451>,
			<16721 16649 16522 16468 16445 16439>,
			<16721 16651 16528 16462 16443 16437>,
			<16721 16652 16534 16458 16442 16437>,
			<16720 16652 16538 16461 16443 16437>,
			<16724 16650 16541 16467 16446 16439>,
			<16732 16649 16543 16468 16446 16439>,
			<16742 16649 16543 16466 16445 16437>,
			<16756 16657 16539 16458 16434 16428>,
			<16745 16659 16549 16462 16443 16434>,
			<16757 16678 16574 16474 16448 16442>,
			<16773 16709 16603 16483 16455 16448>,
			<16796 16751 16643 16501 16465 16458>,
			<16818 16791 16691 16518 16482 16479>,
			<16834 16816 16721 16510 16451 16444>,
			<16858 16816 16727 16499 16445 16436>,
			<16998 16825 16762 16513 16449 16440>,
			<17375 17016 16848 16548 16467 16454>,
			<17375 17016 16848 16548 16467 16454>,
			<17375 17016 16848 16548 16467 16454>;
	};

	qcom,pc-temp-y5-lut {
		qcom,lut-col-legend = <(-10) 0 10 25 40 50>;
		qcom,lut-row-legend = <10000 9800 9600 9400 9200 9000>,
			<8800 8600 8400 8200 8000 7800>,
			<7600 7400 7200 7000 6800 6600>,
			<6400 6200 6000 5800 5600 5400>,
			<5200 5000 4800 4600 4400 4200>,
			<4000 3800 3600 3400 3200 3000>,
			<2800 2600 2400 2200 2000 1800>,
			<1600 1400 1200 1000 900 800>,
			<700 600 500 400 300 200>,
			<100 0>;
		qcom,lut-data = <14386 12621 15123 16466 21668 24008>,
			<13093 13467 16242 16796 21194 23928>,
			<12513 14341 17193 16963 20734 23414>,
			<12512 15140 17927 17005 20295 22694>,
			<12957 15762 18393 16961 19884 21998>,
			<13724 16101 18537 16871 19507 21554>,
			<16923 16175 18262 16678 18987 21211>,
			<20944 16144 17883 16389 18312 20749>,
			<20522 16126 17766 16001 17598 20154>,
			<15460 16108 17638 15445 16794 19361>,
			<12480 16009 17451 15212 16494 18562>,
			<15902 15659 17083 15719 17308 17618>,
			<20711 15314 16758 16387 18269 16904>,
			<20895 16480 16856 16523 17999 17153>,
			<17970 20820 17452 16411 16833 18122>,
			<15731 22913 18388 16399 16330 18501>,
			<14713 21440 20987 16629 16700 17774>,
			<13955 19716 23314 17051 17276 16997>,
			<14301 19812 23480 18461 17651 17243>,
			<15461 20671 23453 21471 17963 18214>,
			<16043 21052 23390 22876 18627 19342>,
			<15246 20778 22966 22738 21130 21617>,
			<14032 20440 22450 22357 23288 23567>,
			<13396 20948 21643 21696 23030 23476>,
			<12960 22504 20187 20418 21782 22727>,
			<12810 22810 19682 19883 20990 21979>,
			<12828 17884 19929 20491 20556 21115>,
			<12860 12978 20348 20876 20324 20443>,
			<12931 13048 21189 20539 20706 20371>,
			<13047 13866 22374 20215 21647 20581>,
			<13076 13980 22342 20718 22168 20757>,
			<13106 13493 19776 22655 22302 20857>,
			<13196 13232 17834 24380 22454 21014>,
			<13347 13542 18881 25149 23264 22038>,
			<13565 13965 20854 25725 24754 23616>,
			<13650 14086 21784 26145 25301 23874>,
			<13629 14066 22255 25826 24678 22988>,
			<13590 14089 22488 24940 23719 22037>,
			<13508 14261 22446 23869 22240 21549>,
			<13402 14525 22240 22541 20560 21160>,
			<13381 14726 21774 20689 19583 20736>,
			<13192 14754 20659 18764 19090 20294>,
			<13022 14481 19990 19526 19663 20169>,
			<13190 14138 19846 21492 19704 20296>,
			<13409 13965 19090 21450 21132 21949>,
			<13424 14144 17898 20856 18935 20475>,
			<13478 14428 16353 19415 19491 18488>,
			<13840 14262 16710 19646 19306 20914>,
			<14087 14566 16682 18418 19153 20878>,
			<14329 15229 16243 19668 24350 24171>,
			<14312 15696 16382 19496 23426 21521>,
			<13855 15430 15378 20068 22080 22357>,
			<12193 14412 14441 21613 24302 20748>,
			<10853 12095 13825 22994 27289 26596>,
			<10853 12095 13825 22994 27289 26596>,
			<10853 12095 13825 22994 27289 26596>;
	};

	qcom,pc-temp-y6-lut {
		qcom,lut-col-legend = <(-10) 0 10 25 40 50>;
		qcom,lut-row-legend = <10000 9800 9600 9400 9200 9000>,
			<8800 8600 8400 8200 8000 7800>,
			<7600 7400 7200 7000 6800 6600>,
			<6400 6200 6000 5800 5600 5400>,
			<5200 5000 4800 4600 4400 4200>,
			<4000 3800 3600 3400 3200 3000>,
			<2800 2600 2400 2200 2000 1800>,
			<1600 1400 1200 1000 900 800>,
			<700 600 500 400 300 200>,
			<100 0>;
		qcom,lut-data = <6102 5456 5166 5040 5008 5002>,
			<6081 5453 5165 5039 5008 5002>,
			<6061 5449 5164 5039 5008 5003>,
			<6042 5446 5163 5038 5008 5003>,
			<6024 5442 5161 5038 5008 5003>,
			<6007 5438 5160 5038 5008 5004>,
			<5992 5433 5157 5038 5009 5004>,
			<5978 5429 5155 5038 5010 5005>,
			<5955 5424 5155 5039 5011 5006>,
			<5921 5419 5156 5039 5012 5007>,
			<5904 5417 5156 5041 5013 5008>,
			<5913 5432 5158 5042 5014 5009>,
			<5925 5450 5161 5045 5016 5010>,
			<5905 5448 5167 5048 5018 5011>,
			<5807 5426 5178 5051 5020 5013>,
			<5745 5403 5182 5055 5022 5015>,
			<5737 5383 5180 5058 5024 5016>,
			<5733 5365 5176 5062 5026 5018>,
			<5727 5356 5167 5067 5031 5021>,
			<5721 5351 5150 5074 5036 5026>,
			<5715 5345 5137 5075 5037 5027>,
			<5704 5338 5127 5056 5027 5020>,
			<5695 5332 5121 5037 5016 5011>,
			<5696 5328 5117 5032 5011 5007>,
			<5707 5325 5115 5030 5007 5004>,
			<5721 5324 5114 5029 5007 5003>,
			<5735 5326 5115 5030 5007 5004>,
			<5752 5331 5116 5031 5008 5004>,
			<5769 5340 5118 5032 5009 5005>,
			<5788 5355 5119 5033 5011 5007>,
			<5807 5371 5120 5035 5014 5009>,
			<5828 5388 5121 5038 5016 5011>,
			<5850 5407 5121 5040 5018 5013>,
			<5872 5427 5125 5042 5020 5015>,
			<5894 5449 5132 5043 5021 5016>,
			<5918 5472 5139 5043 5021 5016>,
			<5944 5497 5147 5042 5015 5010>,
			<5972 5526 5154 5040 5011 5006>,
			<6001 5560 5163 5039 5010 5006>,
			<6032 5600 5172 5038 5010 5006>,
			<6065 5642 5183 5038 5010 5006>,
			<6100 5688 5194 5039 5011 5007>,
			<6138 5742 5209 5042 5012 5007>,
			<6179 5812 5228 5044 5012 5006>,
			<6235 5884 5245 5042 5009 5004>,
			<6238 5926 5266 5045 5012 5007>,
			<6283 5985 5290 5049 5015 5009>,
			<6341 6052 5325 5054 5018 5013>,
			<6406 6127 5366 5061 5022 5017>,
			<6483 6197 5414 5071 5030 5025>,
			<6585 6264 5460 5069 5019 5012>,
			<6795 6332 5518 5069 5017 5011>,
			<7321 6486 5639 5083 5020 5012>,
			<8302 6961 5877 5107 5029 5020>,
			<8302 6961 5877 5107 5029 5020>,
			<8302 6961 5877 5107 5029 5020>;
	};

};
